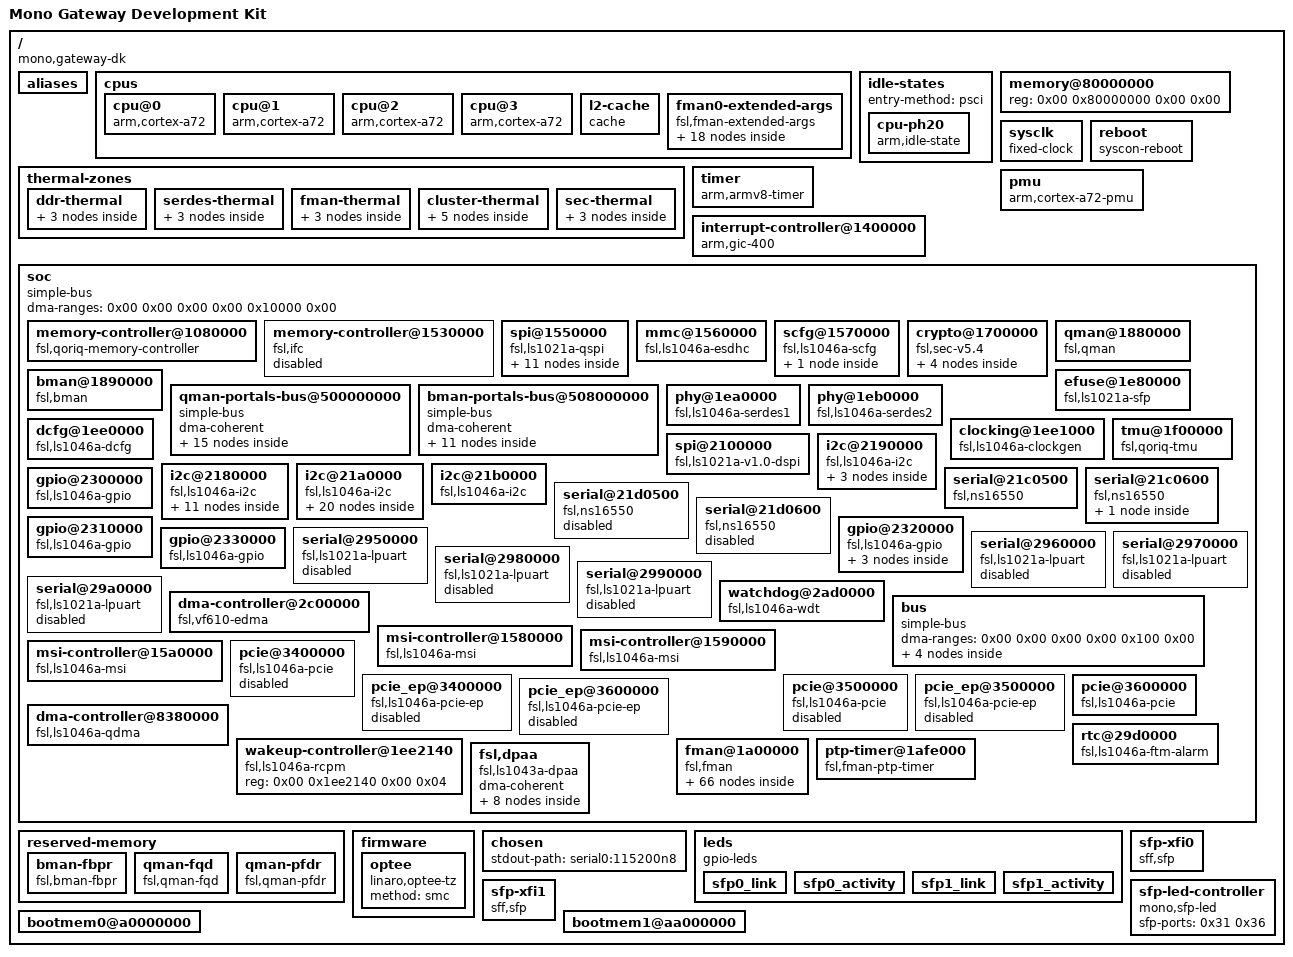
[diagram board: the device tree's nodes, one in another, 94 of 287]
/dts-v1/;

/ {
	compatible = "mono,gateway-dk", "fsl,ls1046a";
	interrupt-parent = <0x01>;
	#address-cells = <0x02>;
	#size-cells = <0x02>;
	model = "Mono Gateway Development Kit";

	aliases {
		crypto = "/soc/crypto@1700000";
		fman0 = "/soc/fman@1a00000";
		ethernet0 = "/soc/fman@1a00000/ethernet@e8000";
		ethernet1 = "/soc/fman@1a00000/ethernet@ea000";
		ethernet2 = "/soc/fman@1a00000/ethernet@e2000";
		ethernet3 = "/soc/fman@1a00000/ethernet@f0000";
		ethernet4 = "/soc/fman@1a00000/ethernet@f2000";
		ethernet5 = "/soc/fman@1a00000/ethernet@ea000";
		ethernet6 = "/soc/fman@1a00000/ethernet@f0000";
		ethernet7 = "/soc/fman@1a00000/ethernet@f2000";
		rtc1 = "/soc/rtc@29d0000";
		qman_fqd = "/reserved-memory/qman-fqd";
		bman_fbpr = "/reserved-memory/bman-fbpr";
		qman_pfdr = "/reserved-memory/qman-pfdr";
		serial0 = "/soc/serial@21c0500";
		serial1 = "/soc/serial@21c0600";
	};

	cpus {
		#address-cells = <0x01>;
		#size-cells = <0x00>;

		cpu@0 {
			device_type = "cpu";
			compatible = "arm,cortex-a72";
			reg = <0x00>;
			clocks = <0x02 0x01 0x00>;
			next-level-cache = <0x03>;
			cpu-idle-states = <0x04>;
			#cooling-cells = <0x02>;
			phandle = <0x08>;
		};

		cpu@1 {
			device_type = "cpu";
			compatible = "arm,cortex-a72";
			reg = <0x01>;
			clocks = <0x02 0x01 0x00>;
			next-level-cache = <0x03>;
			cpu-idle-states = <0x04>;
			#cooling-cells = <0x02>;
			phandle = <0x09>;
		};

		cpu@2 {
			device_type = "cpu";
			compatible = "arm,cortex-a72";
			reg = <0x02>;
			clocks = <0x02 0x01 0x00>;
			next-level-cache = <0x03>;
			cpu-idle-states = <0x04>;
			#cooling-cells = <0x02>;
			phandle = <0x0a>;
		};

		cpu@3 {
			device_type = "cpu";
			compatible = "arm,cortex-a72";
			reg = <0x03>;
			clocks = <0x02 0x01 0x00>;
			next-level-cache = <0x03>;
			cpu-idle-states = <0x04>;
			#cooling-cells = <0x02>;
			phandle = <0x0b>;
		};

		l2-cache {
			compatible = "cache";
			cache-level = <0x02>;
			cache-unified;
			phandle = <0x03>;
		};

		fman0-extended-args {
			cell-index = <0x00>;
			compatible = "fsl,fman-extended-args";
			total-fifo-size = <0x3e500>;

			fman0_oh_0x3-extended-args {
				cell-index = <0x01>;
				compatible = "fsl,fman-port-op-extended-args";
				fifo-size = <0x3200 0x00>;
				buffer-layout = <0x60 0x40>;
			};

			fman0_oh_0x4-extended-args {
				cell-index = <0x02>;
				compatible = "fsl,fman-port-op-extended-args";
				fifo-size = <0x900 0x00>;
				buffer-layout = <0x60 0x40>;
			};

			fman0_rx0-extended-args {
				cell-index = <0x00>;
				compatible = "fsl,fman-port-1g-rx-extended-args";
				fifo-size = <0x3200 0x00>;
				buffer-layout = <0x60 0x40>;
				vsp-window = <0x02 0x00>;
			};

			fman0_tx0-extended-args {
				cell-index = <0x00>;
				compatible = "fsl,fman-port-1g-tx-extended-args";
				fifo-size = <0x3200 0x00>;
				buffer-layout = <0x60 0x40>;
			};

			fman0_rx1-extended-args {
				cell-index = <0x01>;
				compatible = "fsl,fman-port-1g-rx-extended-args";
				fifo-size = <0x3200 0x00>;
				buffer-layout = <0x60 0x40>;
				vsp-window = <0x02 0x00>;
			};

			fman0_tx1-extended-args {
				cell-index = <0x01>;
				compatible = "fsl,fman-port-1g-tx-extended-args";
				fifo-size = <0x3200 0x00>;
				buffer-layout = <0x60 0x40>;
			};

			fman0_rx2-extended-args {
				cell-index = <0x02>;
				compatible = "fsl,fman-port-1g-rx-extended-args";
				fifo-size = <0x3200 0x00>;
				buffer-layout = <0x60 0x40>;
				vsp-window = <0x02 0x00>;
			};

			fman0_tx2-extended-args {
				cell-index = <0x02>;
				compatible = "fsl,fman-port-1g-tx-extended-args";
				fifo-size = <0x3200 0x00>;
				buffer-layout = <0x60 0x40>;
			};

			fman0_rx3-extended-args {
				cell-index = <0x03>;
				compatible = "fsl,fman-port-1g-rx-extended-args";
				fifo-size = <0x3200 0x00>;
				buffer-layout = <0x60 0x40>;
				vsp-window = <0x02 0x00>;
			};

			fman0_tx3-extended-args {
				cell-index = <0x03>;
				compatible = "fsl,fman-port-1g-tx-extended-args";
				fifo-size = <0x3200 0x00>;
				buffer-layout = <0x60 0x40>;
			};

			fman0_rx4-extended-args {
				cell-index = <0x04>;
				compatible = "fsl,fman-port-1g-rx-extended-args";
				fifo-size = <0x3200 0x00>;
				buffer-layout = <0x60 0x40>;
				vsp-window = <0x02 0x00>;
			};

			fman0_tx4-extended-args {
				cell-index = <0x04>;
				compatible = "fsl,fman-port-1g-tx-extended-args";
				fifo-size = <0x3200 0x00>;
				buffer-layout = <0x60 0x40>;
			};

			fman0_rx5-extended-args {
				cell-index = <0x05>;
				compatible = "fsl,fman-port-1g-rx-extended-args";
				fifo-size = <0x3200 0x00>;
				buffer-layout = <0x60 0x40>;
				vsp-window = <0x02 0x00>;
			};

			fman0_tx5-extended-args {
				cell-index = <0x05>;
				compatible = "fsl,fman-port-1g-tx-extended-args";
				fifo-size = <0x3200 0x00>;
				buffer-layout = <0x60 0x40>;
			};

			fman0_rx6-extended-args {
				cell-index = <0x00>;
				compatible = "fsl,fman-port-10g-rx-extended-args";
				fifo-size = <0x6000 0x00>;
				buffer-layout = <0x60 0x40>;
				vsp-window = <0x02 0x00>;
			};

			fman0_tx6-extended-args {
				cell-index = <0x00>;
				compatible = "fsl,fman-port-10g-tx-extended-args";
				fifo-size = <0x4000 0x00>;
				buffer-layout = <0x60 0x40>;
			};

			fman0_rx7-extended-args {
				cell-index = <0x01>;
				compatible = "fsl,fman-port-10g-rx-extended-args";
				fifo-size = <0x6000 0x00>;
				buffer-layout = <0x60 0x40>;
				vsp-window = <0x02 0x00>;
			};

			fman0_tx7-extended-args {
				cell-index = <0x01>;
				compatible = "fsl,fman-port-10g-tx-extended-args";
				fifo-size = <0x4000 0x00>;
				buffer-layout = <0x60 0x40>;
			};
		};
	};

	idle-states {
		entry-method = "psci";

		cpu-ph20 {
			compatible = "arm,idle-state";
			idle-state-name = "PH20";
			arm,psci-suspend-param = <0x00>;
			entry-latency-us = <0x3e8>;
			exit-latency-us = <0x3e8>;
			min-residency-us = <0xbb8>;
			phandle = <0x04>;
		};
	};

	memory@80000000 {
		device_type = "memory";
		reg = <0x00 0x80000000 0x00 0x00>;
	};

	sysclk {
		compatible = "fixed-clock";
		#clock-cells = <0x00>;
		clock-frequency = <0x5f5e100>;
		clock-output-names = "sysclk";
		phandle = <0x0f>;
	};

	reboot {
		compatible = "syscon-reboot";
		regmap = <0x05>;
		offset = <0xb0>;
		mask = <0x02>;
	};

	thermal-zones {

		ddr-thermal {
			polling-delay-passive = <0x3e8>;
			polling-delay = <0x1388>;
			thermal-sensors = <0x06 0x00>;

			trips {

				ddr-ctrler-alert {
					temperature = <0x14c08>;
					hysteresis = <0x7d0>;
					type = "passive";
				};

				ddr-ctrler-crit {
					temperature = <0x17318>;
					hysteresis = <0x7d0>;
					type = "critical";
				};
			};
		};

		serdes-thermal {
			polling-delay-passive = <0x3e8>;
			polling-delay = <0x1388>;
			thermal-sensors = <0x06 0x01>;

			trips {

				serdes-alert {
					temperature = <0x14c08>;
					hysteresis = <0x7d0>;
					type = "passive";
				};

				serdes-crit {
					temperature = <0x17318>;
					hysteresis = <0x7d0>;
					type = "critical";
				};
			};
		};

		fman-thermal {
			polling-delay-passive = <0x3e8>;
			polling-delay = <0x1388>;
			thermal-sensors = <0x06 0x02>;

			trips {

				fman-alert {
					temperature = <0x14c08>;
					hysteresis = <0x7d0>;
					type = "passive";
				};

				fman-crit {
					temperature = <0x17318>;
					hysteresis = <0x7d0>;
					type = "critical";
				};
			};
		};

		cluster-thermal {
			polling-delay-passive = <0x3e8>;
			polling-delay = <0x1388>;
			thermal-sensors = <0x06 0x03>;

			trips {

				core-cluster-alert {
					temperature = <0x14c08>;
					hysteresis = <0x7d0>;
					type = "passive";
					phandle = <0x07>;
				};

				core-cluster-crit {
					temperature = <0x17318>;
					hysteresis = <0x7d0>;
					type = "critical";
				};
			};

			cooling-maps {

				map0 {
					trip = <0x07>;
					cooling-device = <0x08 0xffffffff 0xffffffff 0x09 0xffffffff 0xffffffff 0x0a 0xffffffff 0xffffffff 0x0b 0xffffffff 0xffffffff>;
				};
			};
		};

		sec-thermal {
			polling-delay-passive = <0x3e8>;
			polling-delay = <0x1388>;
			thermal-sensors = <0x06 0x04>;

			trips {

				sec-alert {
					temperature = <0x14c08>;
					hysteresis = <0x7d0>;
					type = "passive";
				};

				sec-crit {
					temperature = <0x17318>;
					hysteresis = <0x7d0>;
					type = "critical";
				};
			};
		};
	};

	timer {
		compatible = "arm,armv8-timer";
		interrupts = <0x01 0x0d 0xf08 0x01 0x0e 0xf08 0x01 0x0b 0xf08 0x01 0x0a 0xf08>;
	};

	pmu {
		compatible = "arm,cortex-a72-pmu";
		interrupts = <0x00 0x6a 0x04 0x00 0x6b 0x04 0x00 0x5f 0x04 0x00 0x61 0x04>;
		interrupt-affinity = <0x08 0x09 0x0a 0x0b>;
	};

	interrupt-controller@1400000 {
		compatible = "arm,gic-400";
		#interrupt-cells = <0x03>;
		interrupt-controller;
		reg = <0x00 0x1410000 0x00 0x10000 0x00 0x1420000 0x00 0x20000 0x00 0x1440000 0x00 0x20000 0x00 0x1460000 0x00 0x20000>;
		interrupts = <0x01 0x09 0xf08>;
		phandle = <0x01>;
	};

	soc {
		compatible = "simple-bus";
		#address-cells = <0x02>;
		#size-cells = <0x02>;
		ranges;
		dma-ranges = <0x00 0x00 0x00 0x00 0x10000 0x00>;

		memory-controller@1080000 {
			compatible = "fsl,qoriq-memory-controller";
			reg = <0x00 0x1080000 0x00 0x1000>;
			interrupts = <0x00 0x90 0x04>;
			dma-coherent;
		};

		memory-controller@1530000 {
			compatible = "fsl,ifc";
			reg = <0x00 0x1530000 0x00 0x10000>;
			interrupts = <0x00 0x2b 0x04>;
			status = "disabled";
			dma-coherent;
		};

		spi@1550000 {
			compatible = "fsl,ls1021a-qspi";
			#address-cells = <0x01>;
			#size-cells = <0x00>;
			reg = <0x00 0x1550000 0x00 0x10000 0x00 0x40000000 0x00 0x10000000>;
			reg-names = "QuadSPI", "QuadSPI-memory";
			interrupts = <0x00 0x63 0x04>;
			clock-names = "qspi_en", "qspi";
			clocks = <0x02 0x04 0x01 0x02 0x04 0x01>;
			status = "okay";
			dma-coherent;

			flash@0 {
				#address-cells = <0x01>;
				#size-cells = <0x01>;
				compatible = "jedec,spi-nor";
				spi-max-frequency = <0x2faf080>;
				reg = <0x00>;

				partitions {
					compatible = "fixed-partitions";
					#address-cells = <0x01>;
					#size-cells = <0x01>;

					partition@flash {
						label = "flash";
						reg = <0x00 0x4000000>;
					};

					partition@0 {
						label = "rcw-bl2";
						reg = <0x00 0x100000>;
					};

					partition@100000 {
						label = "uboot";
						reg = <0x100000 0x200000>;
					};

					partition@300000 {
						label = "uboot-env";
						reg = <0x300000 0x100000>;
					};

					partition@400000 {
						label = "fman-ucode";
						reg = <0x400000 0x100000>;
					};

					partition@500000 {
						label = "recovery-dtb";
						reg = <0x500000 0x100000>;
					};

					partition@600000 {
						label = "backup";
						reg = <0x600000 0x400000>;
					};

					partition@a00000 {
						label = "kernel-initramfs";
						reg = <0xa00000 0x1600000>;
					};

					partition@2000000 {
						label = "unallocated";
						reg = <0x2000000 0x2000000>;
					};
				};
			};
		};

		mmc@1560000 {
			compatible = "fsl,ls1046a-esdhc", "fsl,esdhc";
			reg = <0x00 0x1560000 0x00 0x10000>;
			interrupts = <0x00 0x3e 0x04>;
			clocks = <0x02 0x02 0x01>;
			voltage-ranges = <0x708 0x708 0xce4 0xce4>;
			sdhci,auto-cmd12;
			bus-width = <0x04>;
			status = "okay";
			mmc-hs200-1_8v;
			dma-coherent;
		};

		scfg@1570000 {
			compatible = "fsl,ls1046a-scfg", "syscon";
			reg = <0x00 0x1570000 0x00 0x10000>;
			big-endian;
			#address-cells = <0x01>;
			#size-cells = <0x01>;
			ranges = <0x00 0x00 0x1570000 0x10000>;
			dma-coherent;

			interrupt-controller@1ac {
				compatible = "fsl,ls1046a-extirq", "fsl,ls1043a-extirq";
				#interrupt-cells = <0x02>;
				#address-cells = <0x00>;
				interrupt-controller;
				reg = <0x1ac 0x04>;
				interrupt-map = <0x00 0x00 0x01 0x00 0x83 0x04 0x01 0x00 0x01 0x00 0x84 0x04 0x02 0x00 0x01 0x00 0x85 0x04 0x03 0x00 0x01 0x00 0x87 0x04 0x04 0x00 0x01 0x00 0x88 0x04 0x05 0x00 0x01 0x00 0x89 0x04 0x06 0x00 0x01 0x00 0x91 0x04 0x07 0x00 0x01 0x00 0x92 0x04 0x08 0x00 0x01 0x00 0x93 0x04 0x09 0x00 0x01 0x00 0x95 0x04 0x0a 0x00 0x01 0x00 0x96 0x04 0x0b 0x00 0x01 0x00 0x97 0x04>;
				interrupt-map-mask = <0x0f 0x00>;
			};
		};

		crypto@1700000 {
			compatible = "fsl,sec-v5.4", "fsl,sec-v5.0", "fsl,sec-v4.0";
			fsl,sec-era = <0x08>;
			#address-cells = <0x01>;
			#size-cells = <0x01>;
			ranges = <0x00 0x00 0x1700000 0x100000>;
			reg = <0x00 0x1700000 0x00 0x100000>;
			interrupts = <0x00 0x4b 0x04>;
			dma-coherent;

			jr@10000 {
				compatible = "fsl,sec-v5.4-job-ring", "fsl,sec-v5.0-job-ring", "fsl,sec-v4.0-job-ring";
				reg = <0x10000 0x10000>;
				interrupts = <0x00 0x47 0x04>;
			};

			jr@20000 {
				compatible = "fsl,sec-v5.4-job-ring", "fsl,sec-v5.0-job-ring", "fsl,sec-v4.0-job-ring";
				reg = <0x20000 0x10000>;
				interrupts = <0x00 0x48 0x04>;
			};

			jr@30000 {
				compatible = "fsl,sec-v5.4-job-ring", "fsl,sec-v5.0-job-ring", "fsl,sec-v4.0-job-ring";
				reg = <0x30000 0x10000>;
				interrupts = <0x00 0x49 0x04>;
			};

			jr@40000 {
				compatible = "fsl,sec-v5.4-job-ring", "fsl,sec-v5.0-job-ring", "fsl,sec-v4.0-job-ring";
				reg = <0x40000 0x10000>;
				interrupts = <0x00 0x4a 0x04>;
			};
		};

		qman@1880000 {
			compatible = "fsl,qman";
			reg = <0x00 0x1880000 0x00 0x10000>;
			interrupts = <0x00 0x2d 0x04>;
			memory-region = <0x0c 0x0d>;
			dma-coherent;
		};

		bman@1890000 {
			compatible = "fsl,bman";
			reg = <0x00 0x1890000 0x00 0x10000>;
			interrupts = <0x00 0x2d 0x04>;
			memory-region = <0x0e>;
			dma-coherent;
		};

		qman-portals-bus@500000000 {
			ranges = <0x00 0x05 0x00 0x8000000>;
			#address-cells = <0x01>;
			#size-cells = <0x01>;
			compatible = "simple-bus";
			dma-coherent;

			qman-portal@0 {
				compatible = "fsl,qman-portal";
				reg = <0x00 0x4000 0x4000000 0x4000>;
				interrupts = <0x00 0xac 0x04>;
				cell-index = <0x00>;
			};

			qman-portal@10000 {
				compatible = "fsl,qman-portal";
				reg = <0x10000 0x4000 0x4010000 0x4000>;
				interrupts = <0x00 0xae 0x04>;
				cell-index = <0x01>;
			};

			qman-portal@20000 {
				compatible = "fsl,qman-portal";
				reg = <0x20000 0x4000 0x4020000 0x4000>;
				interrupts = <0x00 0xb0 0x04>;
				cell-index = <0x02>;
			};

			qman-portal@30000 {
				compatible = "fsl,qman-portal";
				reg = <0x30000 0x4000 0x4030000 0x4000>;
				interrupts = <0x00 0xb2 0x04>;
				cell-index = <0x03>;
			};

			qman-portal@40000 {
				compatible = "fsl,qman-portal";
				reg = <0x40000 0x4000 0x4040000 0x4000>;
				interrupts = <0x00 0xb4 0x04>;
				cell-index = <0x04>;
			};

			qman-portal@50000 {
				compatible = "fsl,qman-portal";
				reg = <0x50000 0x4000 0x4050000 0x4000>;
				interrupts = <0x00 0xb6 0x04>;
				cell-index = <0x05>;
			};

			qman-portal@60000 {
				compatible = "fsl,qman-portal";
				reg = <0x60000 0x4000 0x4060000 0x4000>;
				interrupts = <0x00 0xb8 0x04>;
				cell-index = <0x06>;
			};

			qman-portal@70000 {
				compatible = "fsl,qman-portal";
				reg = <0x70000 0x4000 0x4070000 0x4000>;
				interrupts = <0x00 0xba 0x04>;
				cell-index = <0x07>;
			};

			qman-portal@80000 {
				compatible = "fsl,qman-portal";
				reg = <0x80000 0x4000 0x4080000 0x4000>;
				interrupts = <0x00 0xbc 0x04>;
				cell-index = <0x08>;
			};

			qman-portal@90000 {
				compatible = "fsl,qman-portal";
				reg = <0x90000 0x4000 0x4090000 0x4000>;
				interrupts = <0x00 0xbe 0x04>;
				cell-index = <0x09>;
			};

			qman-fqids@0 {
				compatible = "fsl,fqid-range";
				fsl,fqid-range = <0x100 0x100>;
			};

			qman-fqids@1 {
				compatible = "fsl,fqid-range";
				fsl,fqid-range = <0x8000 0x8000>;
			};

			qman-pools@0 {
				compatible = "fsl,pool-channel-range";
				fsl,pool-channel-range = <0x401 0x0f>;
			};

			qman-cgrids@0 {
				compatible = "fsl,cgrid-range";
				fsl,cgrid-range = <0x00 0x100>;
			};

			qman-ceetm@0 {
				compatible = "fsl,qman-ceetm";
				fsl,ceetm-lfqid-range = <0xf00000 0x1000>;
				fsl,ceetm-sp-range = <0x00 0x10>;
				fsl,ceetm-lni-range = <0x00 0x08>;
				fsl,ceetm-channel-range = <0x00 0x20>;
			};
		};

		bman-portals-bus@508000000 {
			ranges = <0x00 0x05 0x8000000 0x8000000>;
			#address-cells = <0x01>;
			#size-cells = <0x01>;
			compatible = "simple-bus";
			dma-coherent;

			bman-portal@0 {
				compatible = "fsl,bman-portal";
				reg = <0x00 0x4000 0x4000000 0x4000>;
				interrupts = <0x00 0xad 0x04>;
				cell-index = <0x00>;
			};

			bman-portal@10000 {
				compatible = "fsl,bman-portal";
				reg = <0x10000 0x4000 0x4010000 0x4000>;
				interrupts = <0x00 0xaf 0x04>;
				cell-index = <0x01>;
			};

			bman-portal@20000 {
				compatible = "fsl,bman-portal";
				reg = <0x20000 0x4000 0x4020000 0x4000>;
				interrupts = <0x00 0xb1 0x04>;
				cell-index = <0x02>;
			};

			bman-portal@30000 {
				compatible = "fsl,bman-portal";
				reg = <0x30000 0x4000 0x4030000 0x4000>;
				interrupts = <0x00 0xb3 0x04>;
				cell-index = <0x03>;
			};

			bman-portal@40000 {
				compatible = "fsl,bman-portal";
				reg = <0x40000 0x4000 0x4040000 0x4000>;
				interrupts = <0x00 0xb5 0x04>;
				cell-index = <0x04>;
			};

			bman-portal@50000 {
				compatible = "fsl,bman-portal";
				reg = <0x50000 0x4000 0x4050000 0x4000>;
				interrupts = <0x00 0xb7 0x04>;
				cell-index = <0x05>;
			};

			bman-portal@60000 {
				compatible = "fsl,bman-portal";
				reg = <0x60000 0x4000 0x4060000 0x4000>;
				interrupts = <0x00 0xb9 0x04>;
				cell-index = <0x06>;
			};

			bman-portal@70000 {
				compatible = "fsl,bman-portal";
				reg = <0x70000 0x4000 0x4070000 0x4000>;
				interrupts = <0x00 0xbb 0x04>;
				cell-index = <0x07>;
			};

			bman-portal@80000 {
				compatible = "fsl,bman-portal";
				reg = <0x80000 0x4000 0x4080000 0x4000>;
				interrupts = <0x00 0xbd 0x04>;
				cell-index = <0x08>;
			};

			bman-portal@90000 {
				compatible = "fsl,bman-portal";
				reg = <0x90000 0x4000 0x4090000 0x4000>;
				interrupts = <0x00 0xbf 0x04>;
				cell-index = <0x09>;
			};

			bman-bpids@0 {
				compatible = "fsl,bpid-range";
				fsl,bpid-range = <0x20 0x20>;
			};
		};

		efuse@1e80000 {
			compatible = "fsl,ls1021a-sfp";
			reg = <0x00 0x1e80000 0x00 0x10000>;
			clocks = <0x02 0x04 0x03>;
			clock-names = "sfp";
		};

		phy@1ea0000 {
			compatible = "fsl,ls1046a-serdes1", "fsl,lynx-10g";
			reg = <0x00 0x1ea0000 0x00 0xffff>;
			#phy-cells = <0x01>;
			big-endian;
		};

		phy@1eb0000 {
			compatible = "fsl,ls1046a-serdes2", "fsl,lynx-10g";
			reg = <0x00 0x1eb0000 0x00 0xffff>;
			#phy-cells = <0x01>;
			big-endian;
		};

		dcfg@1ee0000 {
			compatible = "fsl,ls1046a-dcfg", "syscon";
			reg = <0x00 0x1ee0000 0x00 0x1000 0x00 0x20140000 0x00 0x1000>;
			reg-names = "dcfg_ccsr", "dcfg_dcsr";
			big-endian;
			dma-coherent;
			phandle = <0x05>;
		};

		clocking@1ee1000 {
			compatible = "fsl,ls1046a-clockgen";
			reg = <0x00 0x1ee1000 0x00 0x1000>;
			#clock-cells = <0x02>;
			clocks = <0x0f>;
			dma-coherent;
			phandle = <0x02>;
		};

		tmu@1f00000 {
			compatible = "fsl,qoriq-tmu";
			reg = <0x00 0x1f00000 0x00 0x10000>;
			interrupts = <0x00 0x21 0x04>;
			fsl,tmu-range = <0xb0000 0x9002a 0x6004c 0x70062>;
			fsl,tmu-calibration = <0x00 0x23 0x01 0x29 0x02 0x2f 0x03 0x36 0x04 0x3c 0x05 0x42 0x06 0x49 0x07 0x4f 0x08 0x55 0x09 0x5c 0x0a 0x62 0x0b 0x68 0x10000 0x22 0x10001 0x2a 0x10002 0x32 0x10003 0x3a 0x10004 0x42 0x10005 0x4a 0x10006 0x52 0x10007 0x5a 0x10008 0x62 0x10009 0x6a 0x20000 0x21 0x20001 0x2b 0x20002 0x35 0x20003 0x3e 0x20004 0x48 0x20005 0x52 0x20006 0x5c 0x30000 0x11 0x30001 0x1a 0x30002 0x24 0x30003 0x2e 0x30004 0x38 0x30005 0x42 0x30006 0x4c 0x30007 0x56>;
			#thermal-sensor-cells = <0x01>;
			dma-coherent;
			phandle = <0x06>;
		};

		spi@2100000 {
			compatible = "fsl,ls1021a-v1.0-dspi";
			#address-cells = <0x01>;
			#size-cells = <0x00>;
			reg = <0x00 0x2100000 0x00 0x10000>;
			interrupts = <0x00 0x40 0x04>;
			clock-names = "dspi";
			clocks = <0x02 0x04 0x01>;
			spi-num-chipselects = <0x05>;
			big-endian;
			status = "okay";
			dma-coherent;
		};

		i2c@2180000 {
			compatible = "fsl,ls1046a-i2c", "fsl,vf610-i2c";
			#address-cells = <0x01>;
			#size-cells = <0x00>;
			reg = <0x00 0x2180000 0x00 0x10000>;
			interrupts = <0x00 0x38 0x04>;
			clocks = <0x02 0x04 0x01>;
			dmas = <0x10 0x01 0x26 0x10 0x01 0x27>;
			dma-names = "rx", "tx";
			status = "okay";
			dma-coherent;

			i2c-mux@70 {
				compatible = "nxp,pca9545";
				reg = <0x70>;
				#address-cells = <0x01>;
				#size-cells = <0x00>;

				i2c@0 {
					#address-cells = <0x01>;
					#size-cells = <0x00>;
					reg = <0x00>;

					retimer@18 {
						compatible = "ti,ds100df410";
						reg = <0x18>;
						status = "okay";
					};
				};

				i2c@1 {
					#address-cells = <0x01>;
					#size-cells = <0x00>;
					reg = <0x01>;

					temp-sensor@4c {
						compatible = "ti,tmp431";
						reg = <0x4c>;
					};
				};

				i2c@2 {
					#address-cells = <0x01>;
					#size-cells = <0x00>;
					reg = <0x02>;

					temp-sensor@4c {
						compatible = "ti,tmp431";
						reg = <0x4c>;
					};
				};

				i2c@3 {
					#address-cells = <0x01>;
					#size-cells = <0x00>;
					reg = <0x03>;

					fan-controller@2e {
						compatible = "microchip,emc2305";
						reg = <0x2e>;
						#address-cells = <0x01>;
						#size-cells = <0x00>;
						#pwm-cells = <0x03>;
						phandle = <0x11>;

						fan@0 {
							reg = <0x00>;
							label = "System Fan 1";
							pwms = <0x11 0x6590 0x01 0x01>;
							#cooling-cells = <0x02>;
						};

						fan@1 {
							reg = <0x01>;
							label = "System Fan 2";
							pwms = <0x11 0x6590 0x01 0x01>;
							#cooling-cells = <0x02>;
						};
					};
				};
			};
		};

		i2c@2190000 {
			compatible = "fsl,ls1046a-i2c", "fsl,vf610-i2c";
			#address-cells = <0x01>;
			#size-cells = <0x00>;
			reg = <0x00 0x2190000 0x00 0x10000>;
			interrupts = <0x00 0x39 0x04>;
			clocks = <0x02 0x04 0x01>;
			scl-gpios = <0x12 0x02 0x06>;
			status = "okay";
			dma-coherent;

			i2c-mux@70 {
				compatible = "nxp,pca9545";
				reg = <0x70>;
				#address-cells = <0x01>;
				#size-cells = <0x00>;

				i2c@0 {
					#address-cells = <0x01>;
					#size-cells = <0x00>;
					reg = <0x00>;
					phandle = <0x42>;
				};

				i2c@1 {
					#address-cells = <0x01>;
					#size-cells = <0x00>;
					reg = <0x01>;
					phandle = <0x45>;
				};
			};
		};

		i2c@21a0000 {
			compatible = "fsl,ls1046a-i2c", "fsl,vf610-i2c";
			#address-cells = <0x01>;
			#size-cells = <0x00>;
			reg = <0x00 0x21a0000 0x00 0x10000>;
			interrupts = <0x00 0x3a 0x04>;
			clocks = <0x02 0x04 0x01>;
			scl-gpios = <0x12 0x0a 0x06>;
			status = "okay";
			dma-coherent;

			i2c-mux@70 {
				compatible = "nxp,pca9545";
				reg = <0x70>;
				#address-cells = <0x01>;
				#size-cells = <0x00>;

				i2c@0 {
					#address-cells = <0x01>;
					#size-cells = <0x00>;
					reg = <0x00>;

					power_sensor@40 {
						compatible = "ti,ina234";
						reg = <0x40>;
						label = "USB Power Delivery";
						#io-channel-cells = <0x01>;
						shunt-resistor = <0x3e8>;
					};

					power_sensor@41 {
						compatible = "ti,ina234";
						reg = <0x41>;
						label = "5V PSU";
						#io-channel-cells = <0x01>;
						shunt-resistor = <0x3e8>;
					};

					power_sensor@42 {
						compatible = "ti,ina234";
						reg = <0x42>;
						label = "1V Core PSU";
						#io-channel-cells = <0x01>;
						shunt-resistor = <0x3e8>;
					};

					power_sensor@43 {
						compatible = "ti,ina234";
						reg = <0x43>;
						label = "1.2V DDR PSU";
						#io-channel-cells = <0x01>;
						shunt-resistor = <0x1388>;
					};
				};

				i2c@1 {
					#address-cells = <0x01>;
					#size-cells = <0x00>;
					reg = <0x01>;

					power_sensor@40 {
						compatible = "ti,ina234";
						reg = <0x40>;
						label = "1.35V SerDes PSU";
						#io-channel-cells = <0x01>;
						shunt-resistor = <0x1388>;
					};

					power_sensor@41 {
						compatible = "ti,ina234";
						reg = <0x41>;
						label = "1.8V PSU";
						#io-channel-cells = <0x01>;
						shunt-resistor = <0x1388>;
					};

					power_sensor@42 {
						compatible = "ti,ina234";
						reg = <0x42>;
						label = "2.5V DDR PSU";
						#io-channel-cells = <0x01>;
						shunt-resistor = <0x1388>;
					};

					power_sensor@43 {
						compatible = "ti,ina234";
						reg = <0x43>;
						label = "3.3V PSU";
						#io-channel-cells = <0x01>;
						shunt-resistor = <0x3e8>;
					};
				};

				i2c@2 {
					#address-cells = <0x01>;
					#size-cells = <0x00>;
					reg = <0x02>;

					rtc@53 {
						compatible = "nxp,pcf2131";
						reg = <0x53>;
						status = "okay";
					};

					hd3ss3220@47 {
						compatible = "ti,hd3ss3220";
						reg = <0x47>;
					};
				};

				i2c@3 {
					#address-cells = <0x01>;
					#size-cells = <0x00>;
					reg = <0x03>;

					lp5810@6c {
						compatible = "ti,lp5812";
						reg = <0x6c>;
						#address-cells = <0x01>;
						#size-cells = <0x00>;

						led@0 {
							reg = <0x00>;
							color = <0x00>;
							label = "status:white";
							led-max-microamp = <0x639c>;
						};

						led@1 {
							reg = <0x01>;
							color = <0x03>;
							label = "status:blue";
							led-max-microamp = <0x639c>;
						};

						led@2 {
							reg = <0x02>;
							color = <0x02>;
							label = "status:green";
							led-max-microamp = <0x639c>;
						};

						led@3 {
							reg = <0x03>;
							color = <0x01>;
							label = "status:red";
							led-max-microamp = <0x639c>;
						};
					};
				};
			};
		};

		i2c@21b0000 {
			compatible = "fsl,ls1046a-i2c", "fsl,vf610-i2c";
			#address-cells = <0x01>;
			#size-cells = <0x00>;
			reg = <0x00 0x21b0000 0x00 0x10000>;
			interrupts = <0x00 0x3b 0x04>;
			clocks = <0x02 0x04 0x01>;
			scl-gpios = <0x12 0x0c 0x06>;
			status = "okay";
			dma-coherent;
		};

		serial@21c0500 {
			compatible = "fsl,ns16550", "ns16550a";
			reg = <0x00 0x21c0500 0x00 0x100>;
			interrupts = <0x00 0x36 0x04>;
			clocks = <0x02 0x04 0x01>;
			status = "okay";
			dma-coherent;
		};

		serial@21c0600 {
			compatible = "fsl,ns16550", "ns16550a";
			reg = <0x00 0x21c0600 0x00 0x100>;
			interrupts = <0x00 0x36 0x04>;
			clocks = <0x02 0x04 0x01>;
			status = "okay";
			uart-has-rtscts;
			dma-coherent;

			bluetooth {
				compatible = "nxp,88w8987-bt";
				fw-init-baudrate = <0x2dc6c0>;
			};
		};

		serial@21d0500 {
			compatible = "fsl,ns16550", "ns16550a";
			reg = <0x00 0x21d0500 0x00 0x100>;
			interrupts = <0x00 0x37 0x04>;
			clocks = <0x02 0x04 0x01>;
			status = "disabled";
			dma-coherent;
		};

		serial@21d0600 {
			compatible = "fsl,ns16550", "ns16550a";
			reg = <0x00 0x21d0600 0x00 0x100>;
			interrupts = <0x00 0x37 0x04>;
			clocks = <0x02 0x04 0x01>;
			status = "disabled";
			dma-coherent;
		};

		gpio@2300000 {
			compatible = "fsl,ls1046a-gpio", "fsl,qoriq-gpio";
			reg = <0x00 0x2300000 0x00 0x10000>;
			interrupts = <0x00 0x42 0x04>;
			gpio-controller;
			#gpio-cells = <0x02>;
			interrupt-controller;
			#interrupt-cells = <0x02>;
			dma-coherent;
		};

		gpio@2310000 {
			compatible = "fsl,ls1046a-gpio", "fsl,qoriq-gpio";
			reg = <0x00 0x2310000 0x00 0x10000>;
			interrupts = <0x00 0x43 0x04>;
			gpio-controller;
			#gpio-cells = <0x02>;
			interrupt-controller;
			#interrupt-cells = <0x02>;
			dma-coherent;
		};

		gpio@2320000 {
			compatible = "fsl,ls1046a-gpio", "fsl,qoriq-gpio";
			reg = <0x00 0x2320000 0x00 0x10000>;
			interrupts = <0x00 0x44 0x04>;
			gpio-controller;
			#gpio-cells = <0x02>;
			interrupt-controller;
			#interrupt-cells = <0x02>;
			dma-coherent;
			phandle = <0x41>;

			2R-enable {
				gpio-hog;
				gpios = <0x06 0x01>;
				output-high;
				line-name = "2r-enable";
			};

			3R-enable {
				gpio-hog;
				gpios = <0x02 0x01>;
				output-low;
				line-name = "3r-enable";
			};

			uart-mux {
				gpio-hog;
				gpios = <0x1a 0x00>;
				output-high;
				line-name = "uart-mux";
			};
		};

		gpio@2330000 {
			compatible = "fsl,ls1046a-gpio", "fsl,qoriq-gpio";
			reg = <0x00 0x2330000 0x00 0x10000>;
			interrupts = <0x00 0x86 0x04>;
			gpio-controller;
			#gpio-cells = <0x02>;
			interrupt-controller;
			#interrupt-cells = <0x02>;
			dma-coherent;
			phandle = <0x12>;
		};

		serial@2950000 {
			compatible = "fsl,ls1021a-lpuart";
			reg = <0x00 0x2950000 0x00 0x1000>;
			interrupts = <0x00 0x30 0x04>;
			clocks = <0x02 0x04 0x00>;
			clock-names = "ipg";
			status = "disabled";
			dma-coherent;
		};

		serial@2960000 {
			compatible = "fsl,ls1021a-lpuart";
			reg = <0x00 0x2960000 0x00 0x1000>;
			interrupts = <0x00 0x31 0x04>;
			clocks = <0x02 0x04 0x01>;
			clock-names = "ipg";
			status = "disabled";
			dma-coherent;
		};

		serial@2970000 {
			compatible = "fsl,ls1021a-lpuart";
			reg = <0x00 0x2970000 0x00 0x1000>;
			interrupts = <0x00 0x32 0x04>;
			clocks = <0x02 0x04 0x01>;
			clock-names = "ipg";
			status = "disabled";
			dma-coherent;
		};

		serial@2980000 {
			compatible = "fsl,ls1021a-lpuart";
			reg = <0x00 0x2980000 0x00 0x1000>;
			interrupts = <0x00 0x33 0x04>;
			clocks = <0x02 0x04 0x01>;
			clock-names = "ipg";
			status = "disabled";
			dma-coherent;
		};

		serial@2990000 {
			compatible = "fsl,ls1021a-lpuart";
			reg = <0x00 0x2990000 0x00 0x1000>;
			interrupts = <0x00 0x34 0x04>;
			clocks = <0x02 0x04 0x01>;
			clock-names = "ipg";
			status = "disabled";
			dma-coherent;
		};

		serial@29a0000 {
			compatible = "fsl,ls1021a-lpuart";
			reg = <0x00 0x29a0000 0x00 0x1000>;
			interrupts = <0x00 0x35 0x04>;
			clocks = <0x02 0x04 0x01>;
			clock-names = "ipg";
			status = "disabled";
			dma-coherent;
		};

		watchdog@2ad0000 {
			compatible = "fsl,ls1046a-wdt", "fsl,imx21-wdt";
			reg = <0x00 0x2ad0000 0x00 0x10000>;
			interrupts = <0x00 0x53 0x04>;
			clocks = <0x02 0x04 0x01>;
			big-endian;
			dma-coherent;
		};

		dma-controller@2c00000 {
			#dma-cells = <0x02>;
			compatible = "fsl,vf610-edma";
			reg = <0x00 0x2c00000 0x00 0x10000 0x00 0x2c10000 0x00 0x10000 0x00 0x2c20000 0x00 0x10000>;
			interrupts = <0x00 0x67 0x04 0x00 0x67 0x04>;
			interrupt-names = "edma-tx", "edma-err";
			dma-channels = <0x20>;
			big-endian;
			clock-names = "dmamux0", "dmamux1";
			clocks = <0x02 0x04 0x01 0x02 0x04 0x01>;
			dma-noncoherent;
			dma-coherent;
			phandle = <0x10>;
		};

		bus {
			#address-cells = <0x02>;
			#size-cells = <0x02>;
			compatible = "simple-bus";
			ranges;
			dma-ranges = <0x00 0x00 0x00 0x00 0x100 0x00>;

			usb@2f00000 {
				compatible = "fsl,ls1046a-dwc3", "snps,dwc3";
				reg = <0x00 0x2f00000 0x00 0x10000>;
				interrupts = <0x00 0x3c 0x04>;
				dr_mode = "host";
				snps,quirk-frame-length-adjustment = <0x20>;
				snps,dis_rxdet_inp3_quirk;
				snps,incr-burst-type-adjustment = <0x01 0x04 0x08 0x10>;
				usb3-lpm-capable;
				dma-coherent;
				status = "okay";
			};

			usb@3000000 {
				compatible = "fsl,ls1046a-dwc3", "snps,dwc3";
				reg = <0x00 0x3000000 0x00 0x10000>;
				interrupts = <0x00 0x3d 0x04>;
				dr_mode = "host";
				snps,quirk-frame-length-adjustment = <0x20>;
				snps,dis_rxdet_inp3_quirk;
				snps,incr-burst-type-adjustment = <0x01 0x04 0x08 0x10>;
				usb3-lpm-capable;
				dma-coherent;
				status = "disabled";
				disable-over-current;
			};

			usb@3100000 {
				compatible = "fsl,ls1046a-dwc3", "snps,dwc3";
				reg = <0x00 0x3100000 0x00 0x10000>;
				interrupts = <0x00 0x3f 0x04>;
				dr_mode = "host";
				snps,quirk-frame-length-adjustment = <0x20>;
				snps,dis_rxdet_inp3_quirk;
				snps,incr-burst-type-adjustment = <0x01 0x04 0x08 0x10>;
				usb3-lpm-capable;
				dma-coherent;
				status = "disabled";
				disable-over-current;
			};

			sata@3200000 {
				compatible = "fsl,ls1046a-ahci";
				reg = <0x00 0x3200000 0x00 0x10000 0x00 0x20140520 0x00 0x04>;
				reg-names = "ahci", "sata-ecc";
				interrupts = <0x00 0x45 0x04>;
				clocks = <0x02 0x04 0x01>;
				dma-coherent;
			};
		};

		msi-controller@1580000 {
			compatible = "fsl,ls1046a-msi";
			msi-controller;
			reg = <0x00 0x1580000 0x00 0x10000>;
			interrupts = <0x00 0x74 0x04 0x00 0x6f 0x04 0x00 0x70 0x04 0x00 0x71 0x04>;
			dma-coherent;
			phandle = <0x13>;
		};

		msi-controller@1590000 {
			compatible = "fsl,ls1046a-msi";
			msi-controller;
			reg = <0x00 0x1590000 0x00 0x10000>;
			interrupts = <0x00 0x7e 0x04 0x00 0x79 0x04 0x00 0x7a 0x04 0x00 0x7b 0x04>;
			dma-coherent;
			phandle = <0x14>;
		};

		msi-controller@15a0000 {
			compatible = "fsl,ls1046a-msi";
			msi-controller;
			reg = <0x00 0x15a0000 0x00 0x10000>;
			interrupts = <0x00 0xa0 0x04 0x00 0x9b 0x04 0x00 0x9c 0x04 0x00 0x9d 0x04>;
			dma-coherent;
			phandle = <0x15>;
		};

		pcie@3400000 {
			compatible = "fsl,ls1046a-pcie";
			reg = <0x00 0x3400000 0x00 0x100000 0x40 0x00 0x00 0x2000>;
			reg-names = "regs", "config";
			interrupts = <0x00 0x75 0x04 0x00 0x76 0x04>;
			interrupt-names = "pme", "aer";
			#address-cells = <0x03>;
			#size-cells = <0x02>;
			device_type = "pci";
			num-viewport = <0x08>;
			bus-range = <0x00 0xff>;
			ranges = <0x81000000 0x00 0x00 0x40 0x10000 0x00 0x10000 0x82000000 0x00 0x40000000 0x40 0x40000000 0x00 0x40000000>;
			msi-parent = <0x13 0x14 0x15>;
			#interrupt-cells = <0x01>;
			interrupt-map-mask = <0x00 0x00 0x00 0x07>;
			interrupt-map = <0x00 0x00 0x00 0x01 0x01 0x00 0x6e 0x04 0x00 0x00 0x00 0x02 0x01 0x00 0x6e 0x04 0x00 0x00 0x00 0x03 0x01 0x00 0x6e 0x04 0x00 0x00 0x00 0x04 0x01 0x00 0x6e 0x04>;
			big-endian;
			status = "disabled";
		};

		pcie_ep@3400000 {
			compatible = "fsl,ls1046a-pcie-ep";
			reg = <0x00 0x3400000 0x00 0x100000 0x40 0x00 0x08 0x00>;
			reg-names = "regs", "addr_space";
			interrupts = <0x00 0x75 0x04>;
			interrupt-names = "pme";
			num-ib-windows = <0x06>;
			num-ob-windows = <0x08>;
			big-endian;
			status = "disabled";
		};

		pcie@3500000 {
			compatible = "fsl,ls1046a-pcie";
			reg = <0x00 0x3500000 0x00 0x100000 0x48 0x00 0x00 0x2000>;
			reg-names = "regs", "config";
			interrupts = <0x00 0x7f 0x04 0x00 0x80 0x04>;
			interrupt-names = "pme", "aer";
			#address-cells = <0x03>;
			#size-cells = <0x02>;
			device_type = "pci";
			num-viewport = <0x08>;
			bus-range = <0x00 0xff>;
			ranges = <0x81000000 0x00 0x00 0x48 0x10000 0x00 0x10000 0x82000000 0x00 0x40000000 0x48 0x40000000 0x00 0x40000000>;
			msi-parent = <0x14 0x15 0x13>;
			#interrupt-cells = <0x01>;
			interrupt-map-mask = <0x00 0x00 0x00 0x07>;
			interrupt-map = <0x00 0x00 0x00 0x01 0x01 0x00 0x78 0x04 0x00 0x00 0x00 0x02 0x01 0x00 0x78 0x04 0x00 0x00 0x00 0x03 0x01 0x00 0x78 0x04 0x00 0x00 0x00 0x04 0x01 0x00 0x78 0x04>;
			big-endian;
			status = "disabled";
		};

		pcie_ep@3500000 {
			compatible = "fsl,ls1046a-pcie-ep";
			reg = <0x00 0x3500000 0x00 0x100000 0x48 0x00 0x08 0x00>;
			reg-names = "regs", "addr_space";
			interrupts = <0x00 0x7f 0x04>;
			interrupt-names = "pme";
			num-ib-windows = <0x06>;
			num-ob-windows = <0x08>;
			big-endian;
			status = "disabled";
		};

		pcie@3600000 {
			compatible = "fsl,ls1046a-pcie";
			reg = <0x00 0x3600000 0x00 0x100000 0x50 0x00 0x00 0x2000>;
			reg-names = "regs", "config";
			interrupts = <0x00 0xa1 0x04 0x00 0xa2 0x04>;
			interrupt-names = "pme", "aer";
			#address-cells = <0x03>;
			#size-cells = <0x02>;
			device_type = "pci";
			num-viewport = <0x08>;
			bus-range = <0x00 0xff>;
			ranges = <0x81000000 0x00 0x00 0x50 0x10000 0x00 0x10000 0x82000000 0x00 0x40000000 0x50 0x40000000 0x00 0x40000000>;
			msi-parent = <0x15 0x13 0x14>;
			#interrupt-cells = <0x01>;
			interrupt-map-mask = <0x00 0x00 0x00 0x07>;
			interrupt-map = <0x00 0x00 0x00 0x01 0x01 0x00 0x9a 0x04 0x00 0x00 0x00 0x02 0x01 0x00 0x9a 0x04 0x00 0x00 0x00 0x03 0x01 0x00 0x9a 0x04 0x00 0x00 0x00 0x04 0x01 0x00 0x9a 0x04>;
			big-endian;
			status = "okay";
		};

		pcie_ep@3600000 {
			compatible = "fsl,ls1046a-pcie-ep";
			reg = <0x00 0x3600000 0x00 0x100000 0x50 0x00 0x08 0x00>;
			reg-names = "regs", "addr_space";
			interrupts = <0x00 0xa1 0x04>;
			interrupt-names = "pme";
			num-ib-windows = <0x06>;
			num-ob-windows = <0x08>;
			big-endian;
			status = "disabled";
		};

		dma-controller@8380000 {
			compatible = "fsl,ls1046a-qdma", "fsl,ls1021a-qdma";
			reg = <0x00 0x8380000 0x00 0x1000 0x00 0x8390000 0x00 0x10000 0x00 0x83a0000 0x00 0x40000>;
			interrupts = <0x00 0x99 0x04 0x00 0x27 0x04 0x00 0x28 0x04 0x00 0x29 0x04 0x00 0x2a 0x04>;
			interrupt-names = "qdma-error", "qdma-queue0", "qdma-queue1", "qdma-queue2", "qdma-queue3";
			#dma-cells = <0x01>;
			dma-channels = <0x08>;
			block-number = <0x01>;
			block-offset = <0x10000>;
			fsl,dma-queues = <0x02>;
			status-sizes = <0x40>;
			queue-sizes = <0x40 0x40>;
			big-endian;
			dma-coherent;
		};

		wakeup-controller@1ee2140 {
			compatible = "fsl,ls1046a-rcpm", "fsl,qoriq-rcpm-2.1+";
			reg = <0x00 0x1ee2140 0x00 0x04>;
			#fsl,rcpm-wakeup-cells = <0x01>;
			phandle = <0x16>;
		};

		rtc@29d0000 {
			compatible = "fsl,ls1046a-ftm-alarm";
			reg = <0x00 0x29d0000 0x00 0x10000>;
			fsl,rcpm-wakeup = <0x16 0x20000>;
			interrupts = <0x00 0x56 0x04>;
			big-endian;
			dma-coherent;
		};

		fman@1a00000 {
			#address-cells = <0x01>;
			#size-cells = <0x01>;
			cell-index = <0x00>;
			compatible = "fsl,fman", "simple-bus";
			ranges = <0x00 0x00 0x1a00000 0xfe000>;
			reg = <0x00 0x1a00000 0x00 0xfe000>;
			interrupts = <0x00 0x2c 0x04 0x00 0x2d 0x04>;
			clocks = <0x02 0x03 0x00>;
			clock-names = "fmanclk";
			fsl,qman-channel-range = <0x800 0x10>;
			ptimer-handle = <0x17>;
			dma-coherent;

			cc {
				compatible = "fsl,fman-cc";
			};

			muram@0 {
				compatible = "fsl,fman-muram";
				reg = <0x00 0x60000>;
			};

			bmi@80000 {
				compatible = "fsl,fman-bmi";
				reg = <0x80000 0x400>;
			};

			qmi@80400 {
				compatible = "fsl,fman-qmi";
				reg = <0x80400 0x400>;
			};

			port@82000 {
				cell-index = <0x00>;
				compatible = "fsl,fman-port-oh";
				reg = <0x82000 0x1000>;
				fsl,qman-channel-id = <0x809>;
			};

			port@83000 {
				cell-index = <0x01>;
				compatible = "fsl,fman-port-oh";
				reg = <0x83000 0x1000>;
				fsl,qman-channel-id = <0x80a>;
				phandle = <0x37>;
			};

			port@84000 {
				cell-index = <0x02>;
				compatible = "fsl,fman-port-oh";
				reg = <0x84000 0x1000>;
				fsl,qman-channel-id = <0x80b>;
				phandle = <0x38>;
			};

			port@85000 {
				cell-index = <0x03>;
				compatible = "fsl,fman-port-oh";
				reg = <0x85000 0x1000>;
				fsl,qman-channel-id = <0x80c>;
			};

			port@86000 {
				cell-index = <0x04>;
				compatible = "fsl,fman-port-oh";
				reg = <0x86000 0x1000>;
				fsl,qman-channel-id = <0x80d>;
			};

			port@87000 {
				cell-index = <0x05>;
				compatible = "fsl,fman-port-oh";
				reg = <0x87000 0x1000>;
				fsl,qman-channel-id = <0x80e>;
			};

			policer@c0000 {
				compatible = "fsl,fman-policer";
				reg = <0xc0000 0x1000>;
			};

			keygen@c1000 {
				compatible = "fsl,fman-keygen";
				reg = <0xc1000 0x1000>;
			};

			dma@c2000 {
				compatible = "fsl,fman-dma";
				reg = <0xc2000 0x1000>;
			};

			fpm@c3000 {
				compatible = "fsl,fman-fpm";
				reg = <0xc3000 0x1000>;
			};

			parser@c7000 {
				compatible = "fsl,fman-parser";
				reg = <0xc7000 0x1000>;
			};

			vsps@dc000 {
				compatible = "fsl,fman-vsps";
				reg = <0xdc000 0x1000>;
			};

			mdio@fc000 {
				#address-cells = <0x01>;
				#size-cells = <0x00>;
				compatible = "fsl,fman-memac-mdio";
				reg = <0xfc000 0x1000>;
				status = "disabled";
			};

			mdio@fd000 {
				#address-cells = <0x01>;
				#size-cells = <0x00>;
				compatible = "fsl,fman-memac-mdio";
				reg = <0xfd000 0x1000>;

				ethernet-phy@0 {
					reg = <0x00>;
					phandle = <0x29>;
				};

				ethernet-phy@1 {
					reg = <0x01>;
					phandle = <0x2d>;
				};

				ethernet-phy@2 {
					reg = <0x02>;
					phandle = <0x1e>;
				};
			};

			port@88000 {
				cell-index = <0x08>;
				compatible = "fsl,fman-v3-port-rx", "fsl,fman-port-1g-rx";
				reg = <0x88000 0x1000>;
				phandle = <0x18>;
			};

			port@a8000 {
				cell-index = <0x28>;
				compatible = "fsl,fman-v3-port-tx", "fsl,fman-port-1g-tx";
				reg = <0xa8000 0x1000>;
				fsl,qman-channel-id = <0x802>;
				phandle = <0x19>;
			};

			ethernet@e0000 {
				cell-index = <0x00>;
				compatible = "fsl,fman-memac";
				reg = <0xe0000 0x1000>;
				fsl,fman-ports = <0x18 0x19>;
				ptp-timer = <0x17>;
				pcsphy-handle = <0x1a>;
				pcs-handle = <0x1a>;
				pcs-handle-names = "qsgmii";
				status = "disabled";
				phandle = <0x39>;
			};

			mdio@e1000 {
				#address-cells = <0x01>;
				#size-cells = <0x00>;
				compatible = "fsl,fman-memac-mdio";
				reg = <0xe1000 0x1000>;

				ethernet-phy@0 {
					reg = <0x00>;
				};
			};

			port@89000 {
				cell-index = <0x09>;
				compatible = "fsl,fman-v3-port-rx", "fsl,fman-port-1g-rx";
				reg = <0x89000 0x1000>;
				phandle = <0x1b>;
			};

			port@a9000 {
				cell-index = <0x29>;
				compatible = "fsl,fman-v3-port-tx", "fsl,fman-port-1g-tx";
				reg = <0xa9000 0x1000>;
				fsl,qman-channel-id = <0x803>;
				phandle = <0x1c>;
			};

			ethernet@e2000 {
				cell-index = <0x01>;
				compatible = "fsl,fman-memac";
				reg = <0xe2000 0x1000>;
				fsl,fman-ports = <0x1b 0x1c>;
				ptp-timer = <0x17>;
				pcsphy-handle = <0x1d>;
				pcs-handle = <0x1d>;
				phy-handle = <0x1e>;
				phy-connection-type = "sgmii";
				status = "okay";
				phandle = <0x3a>;
			};

			mdio@e3000 {
				#address-cells = <0x01>;
				#size-cells = <0x00>;
				compatible = "fsl,fman-memac-mdio";
				reg = <0xe3000 0x1000>;

				ethernet-phy@0 {
					reg = <0x00>;
					phandle = <0x1d>;
				};
			};

			port@8a000 {
				cell-index = <0x0a>;
				compatible = "fsl,fman-v3-port-rx", "fsl,fman-port-1g-rx";
				reg = <0x8a000 0x1000>;
				phandle = <0x1f>;
			};

			port@aa000 {
				cell-index = <0x2a>;
				compatible = "fsl,fman-v3-port-tx", "fsl,fman-port-1g-tx";
				reg = <0xaa000 0x1000>;
				fsl,qman-channel-id = <0x804>;
				phandle = <0x20>;
			};

			ethernet@e4000 {
				cell-index = <0x02>;
				compatible = "fsl,fman-memac";
				reg = <0xe4000 0x1000>;
				fsl,fman-ports = <0x1f 0x20>;
				ptp-timer = <0x17>;
				pcsphy-handle = <0x21>;
				pcs-handle = <0x21>;
				status = "disabled";
				phandle = <0x3b>;
			};

			mdio@e5000 {
				#address-cells = <0x01>;
				#size-cells = <0x00>;
				compatible = "fsl,fman-memac-mdio";
				reg = <0xe5000 0x1000>;

				ethernet-phy@0 {
					reg = <0x00>;
					phandle = <0x21>;
				};
			};

			port@8b000 {
				cell-index = <0x0b>;
				compatible = "fsl,fman-v3-port-rx", "fsl,fman-port-1g-rx";
				reg = <0x8b000 0x1000>;
				phandle = <0x22>;
			};

			port@ab000 {
				cell-index = <0x2b>;
				compatible = "fsl,fman-v3-port-tx", "fsl,fman-port-1g-tx";
				reg = <0xab000 0x1000>;
				fsl,qman-channel-id = <0x805>;
				phandle = <0x23>;
			};

			ethernet@e6000 {
				cell-index = <0x03>;
				compatible = "fsl,fman-memac";
				reg = <0xe6000 0x1000>;
				fsl,fman-ports = <0x22 0x23>;
				ptp-timer = <0x17>;
				pcsphy-handle = <0x24>;
				pcs-handle = <0x24>;
				status = "disabled";
				phandle = <0x3c>;
			};

			mdio@e7000 {
				#address-cells = <0x01>;
				#size-cells = <0x00>;
				compatible = "fsl,fman-memac-mdio";
				reg = <0xe7000 0x1000>;

				ethernet-phy@0 {
					reg = <0x00>;
					phandle = <0x24>;
				};
			};

			port@8c000 {
				cell-index = <0x0c>;
				compatible = "fsl,fman-v3-port-rx", "fsl,fman-port-1g-rx";
				reg = <0x8c000 0x1000>;
				phandle = <0x25>;
			};

			port@ac000 {
				cell-index = <0x2c>;
				compatible = "fsl,fman-v3-port-tx", "fsl,fman-port-1g-tx";
				reg = <0xac000 0x1000>;
				fsl,qman-channel-id = <0x806>;
				phandle = <0x26>;
			};

			ethernet@e8000 {
				cell-index = <0x04>;
				compatible = "fsl,fman-memac";
				reg = <0xe8000 0x1000>;
				fsl,fman-ports = <0x25 0x26>;
				ptp-timer = <0x17>;
				pcsphy-handle = <0x27 0x28>;
				pcs-handle = <0x27 0x28>;
				pcs-handle-names = "sgmii", "qsgmii";
				phy-handle = <0x29>;
				phy-connection-type = "sgmii";
				status = "okay";
				phandle = <0x3d>;
			};

			mdio@e9000 {
				#address-cells = <0x01>;
				#size-cells = <0x00>;
				compatible = "fsl,fman-memac-mdio";
				reg = <0xe9000 0x1000>;

				ethernet-phy@0 {
					reg = <0x00>;
					phandle = <0x27>;
				};
			};

			port@8d000 {
				cell-index = <0x0d>;
				compatible = "fsl,fman-v3-port-rx", "fsl,fman-port-1g-rx";
				reg = <0x8d000 0x1000>;
				phandle = <0x2a>;
			};

			port@ad000 {
				cell-index = <0x2d>;
				compatible = "fsl,fman-v3-port-tx", "fsl,fman-port-1g-tx";
				reg = <0xad000 0x1000>;
				fsl,qman-channel-id = <0x807>;
				phandle = <0x2b>;
			};

			ethernet@ea000 {
				cell-index = <0x05>;
				compatible = "fsl,fman-memac";
				reg = <0xea000 0x1000>;
				fsl,fman-ports = <0x2a 0x2b>;
				ptp-timer = <0x17>;
				pcsphy-handle = <0x2c 0x2c>;
				pcs-handle = <0x2c 0x2c>;
				pcs-handle-names = "sgmii", "qsgmii";
				phy-handle = <0x2d>;
				phy-connection-type = "sgmii";
				status = "okay";
				phandle = <0x3e>;
			};

			mdio@eb000 {
				#address-cells = <0x01>;
				#size-cells = <0x00>;
				compatible = "fsl,fman-memac-mdio";
				reg = <0xeb000 0x1000>;

				ethernet-phy@0 {
					reg = <0x00>;
					phandle = <0x2c>;
				};

				ethernet-pcs@1 {
					compatible = "fsl,lynx-pcs";
					reg = <0x01>;
					phandle = <0x28>;
				};

				ethernet-pcs@2 {
					compatible = "fsl,lynx-pcs";
					reg = <0x02>;
					phandle = <0x35>;
				};

				ethernet-pcs@3 {
					compatible = "fsl,lynx-pcs";
					reg = <0x03>;
					phandle = <0x1a>;
				};
			};

			port@90000 {
				cell-index = <0x10>;
				compatible = "fsl,fman-v3-port-rx", "fsl,fman-port-10g-rx";
				reg = <0x90000 0x1000>;
				fsl,fman-10g-port;
				phandle = <0x2e>;
			};

			port@b0000 {
				cell-index = <0x30>;
				compatible = "fsl,fman-v3-port-tx", "fsl,fman-port-10g-tx";
				reg = <0xb0000 0x1000>;
				fsl,fman-10g-port;
				fsl,qman-channel-id = <0x800>;
				phandle = <0x2f>;
			};

			ethernet@f0000 {
				cell-index = <0x08>;
				compatible = "fsl,fman-memac";
				reg = <0xf0000 0x1000>;
				fsl,fman-ports = <0x2e 0x2f>;
				pcsphy-handle = <0x30>;
				pcs-handle = <0x30>;
				sfp = <0x31>;
				phy-connection-type = "xgmii";
				pcs-handle-names = "xfi";
				fixed-link = <0x00 0x01 0x2710 0x00 0x00>;
				phandle = <0x3f>;
			};

			mdio@f1000 {
				#address-cells = <0x01>;
				#size-cells = <0x00>;
				compatible = "fsl,fman-memac-mdio";
				reg = <0xf1000 0x1000>;

				ethernet-phy@0 {
					reg = <0x00>;
					phandle = <0x30>;
				};
			};

			port@91000 {
				cell-index = <0x11>;
				compatible = "fsl,fman-v3-port-rx", "fsl,fman-port-10g-rx";
				reg = <0x91000 0x1000>;
				fsl,fman-10g-port;
				phandle = <0x32>;
			};

			port@b1000 {
				cell-index = <0x31>;
				compatible = "fsl,fman-v3-port-tx", "fsl,fman-port-10g-tx";
				reg = <0xb1000 0x1000>;
				fsl,fman-10g-port;
				fsl,qman-channel-id = <0x801>;
				phandle = <0x33>;
			};

			ethernet@f2000 {
				cell-index = <0x09>;
				compatible = "fsl,fman-memac";
				reg = <0xf2000 0x1000>;
				fsl,fman-ports = <0x32 0x33>;
				pcsphy-handle = <0x34 0x35 0x34>;
				pcs-handle = <0x34 0x35 0x34>;
				pcs-handle-names = "sgmii", "qsgmii", "xfi";
				sfp = <0x36>;
				phy-connection-type = "xgmii";
				fixed-link = <0x00 0x01 0x2710 0x00 0x00>;
				phandle = <0x40>;
			};

			mdio@f3000 {
				#address-cells = <0x01>;
				#size-cells = <0x00>;
				compatible = "fsl,fman-memac-mdio";
				reg = <0xf3000 0x1000>;

				ethernet-phy@0 {
					reg = <0x00>;
					phandle = <0x34>;
				};
			};

			dpa-fman0-oh@2 {
				compatible = "fsl,dpa-oh";
				fsl,qman-frame-queues-oh = <0x60 0x01 0x61 0x01>;
				fsl,fman-oh-port = <0x37>;
			};

			dpa-fman0-oh@3 {
				compatible = "fsl,dpa-oh";
				fsl,qman-frame-queues-oh = <0x62 0x01 0x63 0x01>;
				fsl,fman-oh-port = <0x38>;
			};
		};

		ptp-timer@1afe000 {
			compatible = "fsl,fman-ptp-timer", "fsl,fman-rtc";
			reg = <0x00 0x1afe000 0x00 0x1000>;
			interrupts = <0x00 0x2c 0x04>;
			clocks = <0x02 0x03 0x00>;
			fsl,extts-fifo;
			dma-coherent;
			phandle = <0x17>;
		};

		fsl,dpaa {
			compatible = "fsl,ls1043a-dpaa", "simple-bus", "fsl,dpaa";
			dma-coherent;

			ethernet@0 {
				compatible = "fsl,dpa-ethernet";
				fsl,fman-mac = <0x39>;
				dma-coherent;
				status = "disabled";
			};

			ethernet@1 {
				compatible = "fsl,dpa-ethernet";
				fsl,fman-mac = <0x3a>;
				dma-coherent;
			};

			ethernet@2 {
				compatible = "fsl,dpa-ethernet";
				fsl,fman-mac = <0x3b>;
				dma-coherent;
				status = "disabled";
			};

			ethernet@3 {
				compatible = "fsl,dpa-ethernet";
				fsl,fman-mac = <0x3c>;
				dma-coherent;
				status = "disabled";
			};

			ethernet@4 {
				compatible = "fsl,dpa-ethernet";
				fsl,fman-mac = <0x3d>;
				dma-coherent;
			};

			ethernet@5 {
				compatible = "fsl,dpa-ethernet";
				fsl,fman-mac = <0x3e>;
				dma-coherent;
			};

			ethernet@8 {
				compatible = "fsl,dpa-ethernet";
				fsl,fman-mac = <0x3f>;
				dma-coherent;
			};

			ethernet@9 {
				compatible = "fsl,dpa-ethernet";
				fsl,fman-mac = <0x40>;
				dma-coherent;
			};
		};
	};

	reserved-memory {
		#address-cells = <0x02>;
		#size-cells = <0x02>;
		ranges;

		bman-fbpr {
			compatible = "fsl,bman-fbpr";
			size = <0x00 0x1000000>;
			alignment = <0x00 0x1000000>;
			no-map;
			alloc-ranges = <0x00 0x00 0x10000 0x00>;
			phandle = <0x0e>;
		};

		qman-fqd {
			compatible = "fsl,qman-fqd";
			size = <0x00 0x800000>;
			alignment = <0x00 0x800000>;
			no-map;
			alloc-ranges = <0x00 0x00 0x10000 0x00>;
			phandle = <0x0c>;
		};

		qman-pfdr {
			compatible = "fsl,qman-pfdr";
			size = <0x00 0x2000000>;
			alignment = <0x00 0x2000000>;
			no-map;
			alloc-ranges = <0x00 0x00 0x10000 0x00>;
			phandle = <0x0d>;
		};
	};

	firmware {

		optee {
			compatible = "linaro,optee-tz";
			method = "smc";
		};
	};

	chosen {
		stdout-path = "serial0:115200n8";
	};

	leds {
		compatible = "gpio-leds";

		sfp0_link {
			label = "sfp0:link";
			gpios = <0x41 0x11 0x00>;
			default-state = "off";
			phandle = <0x43>;
		};

		sfp0_activity {
			label = "sfp0:activity";
			gpios = <0x41 0x12 0x00>;
			default-state = "off";
			phandle = <0x44>;
		};

		sfp1_link {
			label = "sfp1:link";
			gpios = <0x41 0x0f 0x00>;
			default-state = "off";
			phandle = <0x46>;
		};

		sfp1_activity {
			label = "sfp1:activity";
			gpios = <0x41 0x10 0x00>;
			default-state = "off";
			phandle = <0x47>;
		};
	};

	sfp-xfi0 {
		compatible = "sff,sfp";
		i2c-bus = <0x42>;
		tx-disable-gpios = <0x41 0x0e 0x00>;
		mod-def0-gpios = <0x41 0x0c 0x01>;
		los-gpios = <0x41 0x0b 0x00>;
		maximum-power-milliwatt = <0xbb8>;
		leds = <0x43 0x44>;
		phandle = <0x31>;
	};

	sfp-xfi1 {
		compatible = "sff,sfp";
		i2c-bus = <0x45>;
		tx-disable-gpios = <0x41 0x0d 0x00>;
		mod-def0-gpios = <0x41 0x0a 0x01>;
		los-gpios = <0x41 0x09 0x00>;
		maximum-power-milliwatt = <0xbb8>;
		leds = <0x46 0x47>;
		phandle = <0x36>;
	};

	sfp-led-controller {
		compatible = "mono,sfp-led";
		sfp-ports = <0x31 0x36>;
	};

	bootmem0@a0000000 {
		reg = <0x00 0xa0000000 0x00 0x4000000 0x00 0xa4000000 0x00 0x6000000>;
	};

	bootmem1@aa000000 {
		reg = <0x00 0xaa000000 0x00 0x4000000 0x00 0xae000000 0x00 0x6000000>;
	};
};
